# wiz16b8m4ct3_0_WIZ16B8M4CT3 register map
Vendor: Texas Instruments
Registers are 32-bit, read-write, reset 0x0 unless marked. A register's access mark holds for its fields unless they carry their own. Offsets are as the file gives them; [hi:lo] are bit positions.

## wiz16b8m4ct3_0_WIZ16B8M4CT3 (part 6 of 12)
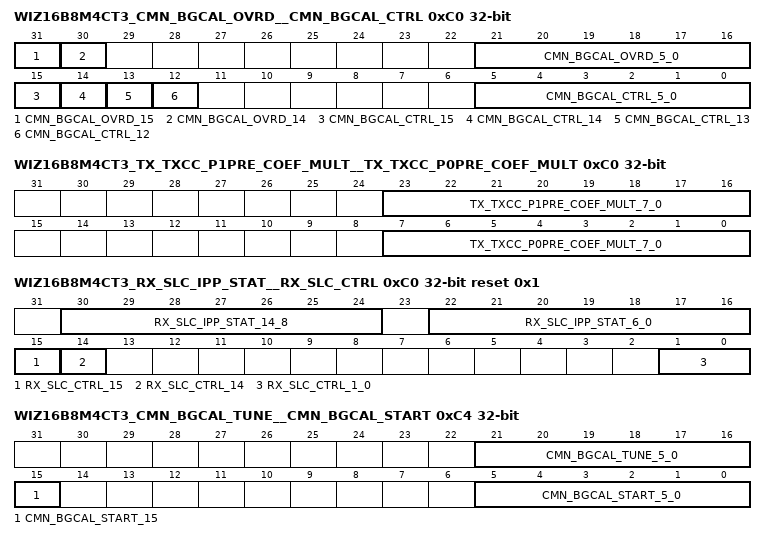
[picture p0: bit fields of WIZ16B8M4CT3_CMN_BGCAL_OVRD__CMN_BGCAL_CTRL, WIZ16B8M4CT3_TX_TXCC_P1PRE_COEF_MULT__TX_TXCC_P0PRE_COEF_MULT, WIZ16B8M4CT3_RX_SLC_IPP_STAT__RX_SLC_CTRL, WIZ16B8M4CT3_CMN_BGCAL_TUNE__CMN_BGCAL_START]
0xC0 WIZ16B8M4CT3_CMN_BGCAL_OVRD__CMN_BGCAL_CTRL access per field
  [31] CMN_BGCAL_OVRD_15 rw — Bandgap code override enable: Activation (1'b1) of this register bit allows the bandgap codes determined during the automatic calibration process to be overridden. The override value is specified using the bandgap code override value field of this register. Note: The value of this field must not be changed while the calibration function is running.
  [30] CMN_BGCAL_OVRD_14 rw — Analog calibration enable override: Activation (1'b1) of this register bit will force the analog calibration circuits to be enabled by activating the cmnda_bias_bgcal_en enable. Note: The value of this field must not be changed while the calibration function is running.
  [21:16] CMN_BGCAL_OVRD_5_0 rw — Bandgap code override value: These bits are used to override the bandgap code determined during the automatic calibration process. The code written to these bits is valid when the bandgap code override enable bit in this register is active. The codes in this field correspond to those described in the bandgap calibration code field in the Bandgap calibration control register on page 106. Note: The value of this field must not be changed while the calibration function is running.
  [15] CMN_BGCAL_CTRL_15 rw — Start bandgap calibration: Activating (1'b1) this bit will start the bandgap calibration process. This signal must remain active until the calibration process is complete. To start another calibration process, this register must first be set inactive (1'b0) until the bandbap calibration process done bit in this register is cleared. Note: This bit is intended to be for diagnostics purposes only. This calibration process is automatically activated internally by the startup state machine. When using this bit, the user must wait until after the internally activated process completes.
  [14] CMN_BGCAL_CTRL_14 ro — Bandgap calibration process done: This bit will be set to 1'b1 when the bandgap calibration process is complete. It will be cleared by cmn_reset_n, or by the deactivation of the start bandgap calibration bit in this register after calibration is complete. Note: This bit is intended to be for diagnostics purposes only. Note: This bit is not likely to be observed as being set after internal automatic calibration is complete, because the internally generated run signal will be driven inactive immediately after the done signal is activated, and therefore the internal done signal will be cleared. Note: Three cmn_ref_clk cycles are required after the start of the calibration process to clear this signal.
  [13] CMN_BGCAL_CTRL_13 ro — No analog calibration response : This signal indicates that the calibration function has gone through the entire calibration process, reached the final calibration value, and the analog has not responded indicating that a valid calibration value has been reached. Note: Due to the nature of the calibration process, it is not possible to determine if the analog responded or not for the lowest code of 5'b10001. The reason for this is, when sequencing to lower codes, the calibration function is looking for the analog response to transition from 1'b1 to 1'b0. If the lowest calibration code is the correct code, the analog will respond with 1'b1, and the algorithm can't sequence to a lower code to look for the transition from 1'b1 to 1'b0. Similarly, if the analog is not responding, it is not possible to sequence to a lower code to detect this. Therefore, even when the calibration function selects this calibration code as valid, this bit will be set.
  [12] CMN_BGCAL_CTRL_12 ro — Current analog comparator response: This is the current state of the analog comparator response signal (cmnda_bias_bgcal_comp). This signal is not synchronized, and is provided for diagnostic purposes only.
  [5:0] CMN_BGCAL_CTRL_5_0 ro — Bandgap calibration code: This is the calibration code that was determined by the bandgap calibration process. The following indicates how this encoding maps to the cmnda_bias_bgcal_up and cmnda_bias_bgcal_azsel signals going to the analog bandgap function. The 6 bit value on the left is the value of this field. The 1 bit value on the right corresponds to the value of cmnda_bias_bgcal_up. The 5 bit field corresponds to the value of cmnda_bias_bgcal_azsel. 6'b011111 : 1'b1, 5'b11111 6'b011110 : 1'b1, 5'b11110 ... 6'b000010 : 1'b1, 5'b00010 6'b000001 : 1'b1, 5'b00001 6'b000000 : 1'b1, 5'b00000 6'b111111 : 1'b0, 5'b00001 6'b111110 : 1'b0, 5'b00010 ... 6'b100010 : 1'b0, 5'b11110 6'b100001 : 1'b0, 5'b11111
0xC0 WIZ16B8M4CT3_TX_TXCC_P1PRE_COEF_MULT__TX_TXCC_P0PRE_COEF_MULT
  [23:16] TX_TXCC_P1PRE_COEF_MULT_7_0 — Preset 1 pre emphasis coefficient multiplier value : The value in this field specifies the multiplier value used to generate the preset 1 pre emphasis coefficient value from the FS value. The following describes the multiplier value each bit in this field corresponds to. Bit 7 : 128/128 = 1.000000 Bit 6 : 64/128 = 0.500000 Bit 5 : 32/128 = 0.250000 Bit 4 : 16/128 = 0.125000 Bit 3 : 8/128 = 0.062500 Bit 2 : 4/128 = 0.031250 Bit 1 : 2/128 = 0.015625 Bit 0 : 1/128 = 0.0078125 Note: The output of the multiplier is 6 bits wide. It is possible to set the multiplier value here to a sufficiently large value to cause the multiplier result to be such that it can't be represented by a 6 bit value. In such a case, the multiplier output will be driven to 6'b111111.
  [7:0] TX_TXCC_P0PRE_COEF_MULT_7_0 — Preset 0 pre emphasis coefficient multiplier value : The value in this field specifies the multiplier value used to generate the preset 0 pre emphasis coefficient value from the FS value. The following describes the multiplier value each bit in this field corresponds to. Bit 7 : 128/128 = 1.000000 Bit 6 : 64/128 = 0.500000 Bit 5 : 32/128 = 0.250000 Bit 4 : 16/128 = 0.125000 Bit 3 : 8/128 = 0.062500 Bit 2 : 4/128 = 0.031250 Bit 1 : 2/128 = 0.015625 Bit 0 : 1/128 = 0.0078125 Note: The output of the multiplier is 6 bits wide. It is possible to set the multiplier value here to a sufficiently large value to cause the multiplier result to be such that it can't be represented by a 6 bit value. In such a case, the multiplier output will be driven to 6'b111111.
0xC0 WIZ16B8M4CT3_RX_SLC_IPP_STAT__RX_SLC_CTRL access per field reset 0x1
  [30:24] RX_SLC_IPP_STAT_14_8 ro — I even latch receiver sampler calibration DAC value: This field contains the current value that the RX sampler latch calibration module has calculated to drive to the DAC that controls the offset for the I even latch in the analog sampler component.
  [22:16] RX_SLC_IPP_STAT_6_0 ro — I odd latch receiver sampler calibration DAC value: This field contains the current value that the RX sampler latch calibration module has calculated to drive to the DAC that controls the offset for the I odd latch in the analog sampler component.
  [15] RX_SLC_CTRL_15 rw — Start RX sampler latch calibration: Activating (1'b1) this bit will start the RX sampler latch calibration process. This bit should remain active until the RX sampler latch calibration process is complete. To start another RX sampler latch calibration process, this bit must first be inactive (1'b0) until the RX sampler latch calibration done bit goes inactive. Note: This bit is intended to be for diagnostics purposes only. This calibration process is automatically activated internally, by the power state machine. When using this bit, the user must wait until after the internally activated process completes.
  [14] RX_SLC_CTRL_14 ro — RX sampler latch calibration process done: This bit will be set to 1'b1 when the RX sampler latch calibration process is complete. It will be cleared by cmn_reset_n, or by clearing the start RX sampler latch process bit. Note: This bit is intended to be for diagnostics purposes only. Note: This bit is not likely to be observed as being set after internal automatic calibration is complete, because the internally generated run signal will be driven inactive immediately after the done signal is activated, and therefore the internal done signal will be cleared.
  [1:0] RX_SLC_CTRL_1_0 rw — RX sampler latch calibration scaler: This field specifies the scaler value used for the input data accumulator. The following is the encoding used for this signal.
0xC4 WIZ16B8M4CT3_CMN_BGCAL_TUNE__CMN_BGCAL_START
  [21:16] CMN_BGCAL_TUNE_5_0 — Bandgap calibration tune value: The value of this field is added to the automatically calibrated code, or the override code if override is enabled. Note: This value is a twos complement value, so the calibrated code can be increased or decreased.
  [15] CMN_BGCAL_START_15 — Bandgap calibration direction: This controls the direction that the automatic calibration process steps the calibration codes in. 1'b0 : From 4'b1001 to 4'b0111. 1'b1 : From 4'b0111 to 4'b0000.
  [5:0] CMN_BGCAL_START_5_0 — Start bandgap calibration code: This is the calibration code that the calibration process starts with when automatic calibration is run. The codes in this field correspond to those described in the bandgap calibration code field in the Bandgap calibration control register on page 106.
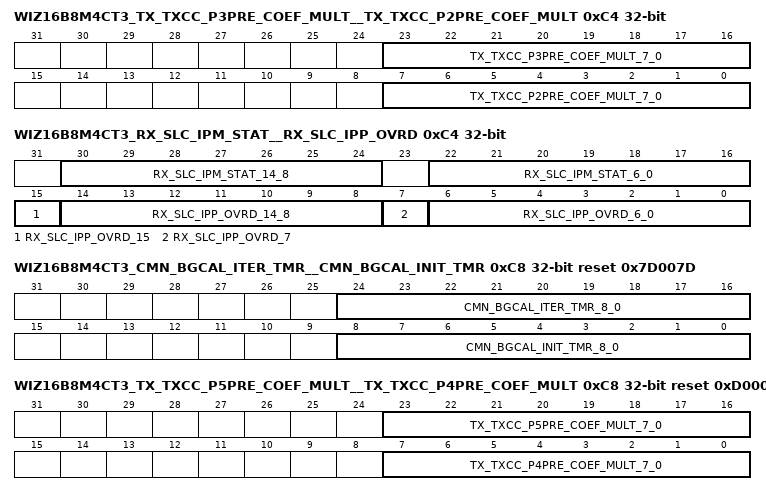
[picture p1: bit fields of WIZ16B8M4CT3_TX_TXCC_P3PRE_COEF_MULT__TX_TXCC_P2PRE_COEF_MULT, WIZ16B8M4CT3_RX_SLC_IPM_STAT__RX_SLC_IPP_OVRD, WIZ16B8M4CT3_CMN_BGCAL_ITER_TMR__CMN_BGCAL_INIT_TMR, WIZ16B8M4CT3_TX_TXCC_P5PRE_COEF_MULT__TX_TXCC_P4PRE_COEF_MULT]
0xC4 WIZ16B8M4CT3_TX_TXCC_P3PRE_COEF_MULT__TX_TXCC_P2PRE_COEF_MULT
  [23:16] TX_TXCC_P3PRE_COEF_MULT_7_0 — Preset 3 pre emphasis coefficient multiplier value : The value in this field specifies the multiplier value used to generate the preset 3 pre emphasis coefficient value from the FS value. The following describes the multiplier value each bit in this field corresponds to. Bit 7 : 128/128 = 1.000000 Bit 6 : 64/128 = 0.500000 Bit 5 : 32/128 = 0.250000 Bit 4 : 16/128 = 0.125000 Bit 3 : 8/128 = 0.062500 Bit 2 : 4/128 = 0.031250 Bit 1 : 2/128 = 0.015625 Bit 0 : 1/128 = 0.0078125 Note: The output of the multiplier is 6 bits wide. It is possible to set the multiplier value here to a sufficiently large value to cause the multiplier result to be such that it can't be represented by a 6 bit value. In such a case, the multiplier output will be driven to 6'b111111.
  [7:0] TX_TXCC_P2PRE_COEF_MULT_7_0 — Preset 2 pre emphasis coefficient multiplier value : The value in this field specifies the multiplier value used to generate the preset 2 pre emphasis coefficient value from the FS value. The following describes the multiplier value each bit in this field corresponds to. Bit 7 : 128/128 = 1.000000 Bit 6 : 64/128 = 0.500000 Bit 5 : 32/128 = 0.250000 Bit 4 : 16/128 = 0.125000 Bit 3 : 8/128 = 0.062500 Bit 2 : 4/128 = 0.031250 Bit 1 : 2/128 = 0.015625 Bit 0 : 1/128 = 0.0078125 Note: The output of the multiplier is 6 bits wide. It is possible to set the multiplier value here to a sufficiently large value to cause the multiplier result to be such that it can't be represented by a 6 bit value. In such a case, the multiplier output will be driven to 6'b111111.
0xC4 WIZ16B8M4CT3_RX_SLC_IPM_STAT__RX_SLC_IPP_OVRD access per field
  [30:24] RX_SLC_IPM_STAT_14_8 ro — I even latch receiver sampler calibration DAC value: This field contains the current value that the RX sampler latch calibration module has calculated to drive to the DAC that controls the offset for the I even latch in the analog sampler component.
  [22:16] RX_SLC_IPM_STAT_6_0 ro — I odd latch receiver sampler calibration DAC value: This field contains the current value that the RX sampler latch calibration module has calculated to drive to the DAC that controls the offset for the I odd latch in the analog sampler component.
  [15] RX_SLC_IPP_OVRD_15 rw — I even latch receiver sampler calibration DAC override enable: When this bit is active (1'b1), the value in the I even latch receiver sampler calibration DAC override value field of this register will override the calibrated value for the I even sampler latch.
  [14:8] RX_SLC_IPP_OVRD_14_8 rw — I even latch receiver sampler calibration DAC override value: This field contains the value that can be used to override the calibrated value for the I even sampler latch. Note: The value of this field is a signed magnitude number with a range of 5'b11111 (min) to 5'b01111 (max). A value of 5'b10000 (-0) is not valid.
  [7] RX_SLC_IPP_OVRD_7 rw — I odd latch receiver sampler calibration DAC override enable: When this bit is active (1'b1), the value in the I odd latch receiver sampler calibration DAC override value field of this register will override the calibrated value for the I odd sampler latch.
  [6:0] RX_SLC_IPP_OVRD_6_0 rw — I odd latch receiver sampler calibration DAC override value: This field contains the value that can be used to override the calibrated value for the I odd sampler latch. Note: The value of this field is a signed magnitude number with a range of 5'b11111 (min) to 5'b01111 (max). A value of 5'b10000 (-0) is not valid.
0xC8 WIZ16B8M4CT3_CMN_BGCAL_ITER_TMR__CMN_BGCAL_INIT_TMR reset 0x7D007D
  [24:16] CMN_BGCAL_ITER_TMR_8_0 — Iteration wait timer value: This is the number of cmn_ref_clk clocks to wait between when a value is placed on the bandgap calibration signals going to the analog, and when the comparator value coming from the analog circuits can be checked. Note: This results in the minimum number of cmn_ref_clk clocks required to wait 5 uSec. Note: This should never be set to a value of less than 3.
  [8:0] CMN_BGCAL_INIT_TMR_8_0 — Initialization wait timer value: This is the number of cmn_ref_clk clocks to wait between when the analog bandgap calibration circuits are enabled, and when the first values are placed on the bandgap calibration signals going to the analog. Note: This results in the minimum number of cmn_ref_clk clocks required to wait 5 uSec. Note: This should never be set to a value of less than 1.
0xC8 WIZ16B8M4CT3_TX_TXCC_P5PRE_COEF_MULT__TX_TXCC_P4PRE_COEF_MULT reset 0xD0000
  [23:16] TX_TXCC_P5PRE_COEF_MULT_7_0 — Preset 5 pre emphasis coefficient multiplier value : The value in this field specifies the multiplier value used to generate the preset 5 pre emphasis coefficient value from the FS value. The following describes the multiplier value each bit in this field corresponds to. Bit 7 : 128/128 = 1.000000 Bit 6 : 64/128 = 0.500000 Bit 5 : 32/128 = 0.250000 Bit 4 : 16/128 = 0.125000 Bit 3 : 8/128 = 0.062500 Bit 2 : 4/128 = 0.031250 Bit 1 : 2/128 = 0.015625 Bit 0 : 1/128 = 0.0078125 Note: The output of the multiplier is 6 bits wide. It is possible to set the multiplier value here to a sufficiently large value to cause the multiplier result to be such that it can't be represented by a 6 bit value. In such a case, the multiplier output will be driven to 6'b111111.
  [7:0] TX_TXCC_P4PRE_COEF_MULT_7_0 — Preset 4 pre emphasis coefficient multiplier value : The value in this field specifies the multiplier value used to generate the preset 4 pre emphasis coefficient value from the FS value. The following describes the multiplier value each bit in this field corresponds to. Bit 7 : 128/128 = 1.000000 Bit 6 : 64/128 = 0.500000 Bit 5 : 32/128 = 0.250000 Bit 4 : 16/128 = 0.125000 Bit 3 : 8/128 = 0.062500 Bit 2 : 4/128 = 0.031250 Bit 1 : 2/128 = 0.015625 Bit 0 : 1/128 = 0.0078125 Note: The output of the multiplier is 6 bits wide. It is possible to set the multiplier value here to a sufficiently large value to cause the multiplier result to be such that it can't be represented by a 6 bit value. In such a case, the multiplier output will be driven to 6'b111111.
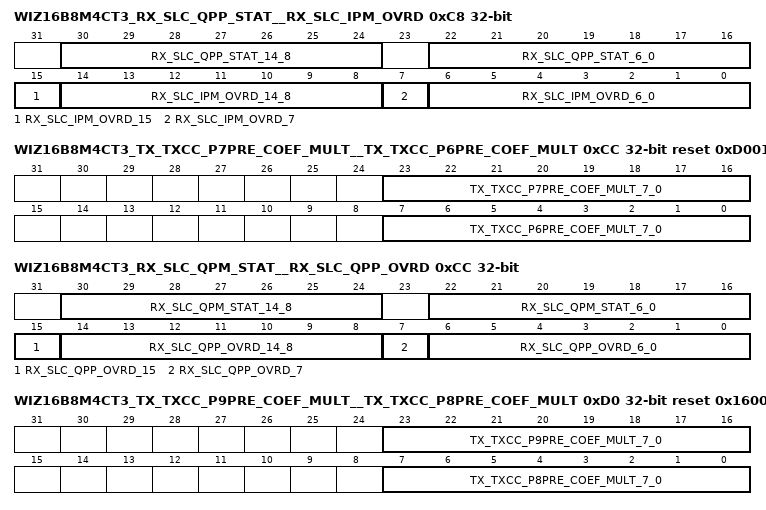
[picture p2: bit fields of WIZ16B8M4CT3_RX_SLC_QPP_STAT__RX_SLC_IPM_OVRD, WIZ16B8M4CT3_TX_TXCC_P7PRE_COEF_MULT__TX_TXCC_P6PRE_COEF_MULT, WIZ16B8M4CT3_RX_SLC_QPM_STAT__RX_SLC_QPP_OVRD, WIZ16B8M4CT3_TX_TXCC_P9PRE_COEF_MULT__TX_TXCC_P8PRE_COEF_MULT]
0xC8 WIZ16B8M4CT3_RX_SLC_QPP_STAT__RX_SLC_IPM_OVRD access per field
  [30:24] RX_SLC_QPP_STAT_14_8 ro — Q even latch receiver sampler calibration DAC value: This field contains the current value that the RX sampler latch calibration module has calculated to drive to the DAC that controls the offset for the Q even latch in the analog sampler component.
  [22:16] RX_SLC_QPP_STAT_6_0 ro — Q odd latch receiver sampler calibration DAC value: This field contains the current value that the RX sampler latch calibration module has calculated to drive to the DAC that controls the offset for the Q odd latch in the analog sampler component.
  [15] RX_SLC_IPM_OVRD_15 rw — I eve latch receiver sampler calibration DAC override enable: When this bit is active (1'b1), the value in the I even latch receiver sampler calibration DAC override value field of this register will override the calibrated value for the I even sampler latch.
  [14:8] RX_SLC_IPM_OVRD_14_8 rw — I even latch receiver sampler calibration DAC override value: This field contains the value that can be used to override the calibrated value for the I even sampler latch. Note: The value of this field is a signed magnitude number with a range of 5'b11111 (min) to 5'b01111 (max). A value of 5'b10000 (-0) is not valid.
  [7] RX_SLC_IPM_OVRD_7 rw — I odd latch receiver sampler calibration DAC override enable: When this bit is active (1'b1), the value in the I odd latch receiver sampler calibration DAC override value field of this register will override the calibrated value for the I odd sampler latch.
  [6:0] RX_SLC_IPM_OVRD_6_0 rw — I odd latch receiver sampler calibration DAC override value: This field contains the value that can be used to override the calibrated value for the I odd sampler latch. Note: The value of this field is a signed magnitude number with a range of 5'b11111 (min) to 5'b01111 (max). A value of 5'b10000 (-0) is not valid.
0xCC WIZ16B8M4CT3_TX_TXCC_P7PRE_COEF_MULT__TX_TXCC_P6PRE_COEF_MULT reset 0xD0010
  [23:16] TX_TXCC_P7PRE_COEF_MULT_7_0 — Preset 7 pre emphasis coefficient multiplier value : The value in this field specifies the multiplier value used to generate the preset 7 pre emphasis coefficient value from the FS value. The following describes the multiplier value each bit in this field corresponds to. Bit 7 : 128/128 = 1.000000 Bit 6 : 64/128 = 0.500000 Bit 5 : 32/128 = 0.250000 Bit 4 : 16/128 = 0.125000 Bit 3 : 8/128 = 0.062500 Bit 2 : 4/128 = 0.031250 Bit 1 : 2/128 = 0.015625 Bit 0 : 1/128 = 0.0078125 Note: The output of the multiplier is 6 bits wide. It is possible to set the multiplier value here to a sufficiently large value to cause the multiplier result to be such that it can't be represented by a 6 bit value. In such a case, the multiplier output will be driven to 6'b111111.
  [7:0] TX_TXCC_P6PRE_COEF_MULT_7_0 — Preset 6 pre emphasis coefficient multiplier value : The value in this field specifies the multiplier value used to generate the preset 6 pre emphasis coefficient value from the FS value. The following describes the multiplier value each bit in this field corresponds to. Bit 7 : 128/128 = 1.000000 Bit 6 : 64/128 = 0.500000 Bit 5 : 32/128 = 0.250000 Bit 4 : 16/128 = 0.125000 Bit 3 : 8/128 = 0.062500 Bit 2 : 4/128 = 0.031250 Bit 1 : 2/128 = 0.015625 Bit 0 : 1/128 = 0.0078125 Note: The output of the multiplier is 6 bits wide. It is possible to set the multiplier value here to a sufficiently large value to cause the multiplier result to be such that it can't be represented by a 6 bit value. In such a case, the multiplier output will be driven to 6'b111111.
0xCC WIZ16B8M4CT3_RX_SLC_QPM_STAT__RX_SLC_QPP_OVRD access per field
  [30:24] RX_SLC_QPM_STAT_14_8 ro — Q even latch receiver sampler calibration DAC value: This field contains the current value that the RX sampler latch calibration module has calculated to drive to the DAC that controls the offset for the Q even latch in the analog sampler component.
  [22:16] RX_SLC_QPM_STAT_6_0 ro — Q odd latch receiver sampler calibration DAC value: This field contains the current value that the RX sampler latch calibration module has calculated to drive to the DAC that controls the offset for the Q odd latch in the analog sampler component.
  [15] RX_SLC_QPP_OVRD_15 rw — Q even latch receiver sampler calibration DAC override enable: When this bit is active (1'b1), the value in the Q even latch receiver sampler calibration DAC override value field of this register will override the calibrated value for the Q even sampler latch.
  [14:8] RX_SLC_QPP_OVRD_14_8 rw — Q even latch receiver sampler calibration DAC override value: This field contains the value that can be used to override the calibrated value for the Q even sampler latch. Note: The value of this field is a signed magnitude number with a range of 5'b11111 (min) to 5'b01111 (max). A value of 5'b10000 (-0) is not valid.
  [7] RX_SLC_QPP_OVRD_7 rw — Q odd latch receiver sampler calibration DAC override enable: When this bit is active (1'b1), the value in the Q odd latch receiver sampler calibration DAC override value field of this register will override the calibrated value for the Q odd sampler latch.
  [6:0] RX_SLC_QPP_OVRD_6_0 rw — Q odd latch receiver sampler calibration DAC override value: This field contains the value that can be used to override the calibrated value for the Q odd sampler latch. Note: The value of this field is a signed magnitude number with a range of 5'b11111 (min) to 5'b01111 (max). A value of 5'b10000 (-0) is not valid.
0xD0 WIZ16B8M4CT3_TX_TXCC_P9PRE_COEF_MULT__TX_TXCC_P8PRE_COEF_MULT reset 0x160010
  [23:16] TX_TXCC_P9PRE_COEF_MULT_7_0 — Preset 9 pre emphasis coefficient multiplier value : The value in this field specifies the multiplier value used to generate the preset 9 pre emphasis coefficient value from the FS value. The following describes the multiplier value each bit in this field corresponds to. Bit 7 : 128/128 = 1.000000 Bit 6 : 64/128 = 0.500000 Bit 5 : 32/128 = 0.250000 Bit 4 : 16/128 = 0.125000 Bit 3 : 8/128 = 0.062500 Bit 2 : 4/128 = 0.031250 Bit 1 : 2/128 = 0.015625 Bit 0 : 1/128 = 0.0078125 Note: The output of the multiplier is 6 bits wide. It is possible to set the multiplier value here to a sufficiently large value to cause the multiplier result to be such that it can't be represented by a 6 bit value. In such a case, the multiplier output will be driven to 6'b111111.
  [7:0] TX_TXCC_P8PRE_COEF_MULT_7_0 — Preset 8 pre emphasis coefficient multiplier value : The value in this field specifies the multiplier value used to generate the preset 8 pre emphasis coefficient value from the FS value. The following describes the multiplier value each bit in this field corresponds to. Bit 7 : 128/128 = 1.000000 Bit 6 : 64/128 = 0.500000 Bit 5 : 32/128 = 0.250000 Bit 4 : 16/128 = 0.125000 Bit 3 : 8/128 = 0.062500 Bit 2 : 4/128 = 0.031250 Bit 1 : 2/128 = 0.015625 Bit 0 : 1/128 = 0.0078125 Note: The output of the multiplier is 6 bits wide. It is possible to set the multiplier value here to a sufficiently large value to cause the multiplier result to be such that it can't be represented by a 6 bit value. In such a case, the multiplier output will be driven to 6'b111111.
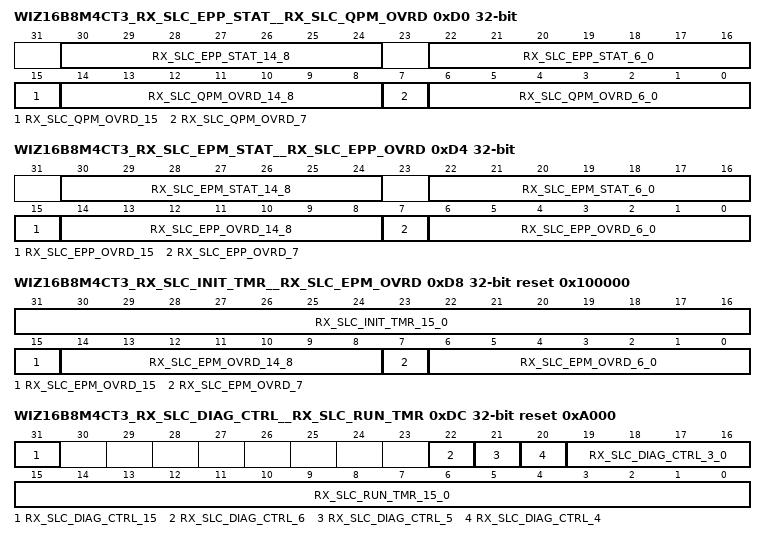
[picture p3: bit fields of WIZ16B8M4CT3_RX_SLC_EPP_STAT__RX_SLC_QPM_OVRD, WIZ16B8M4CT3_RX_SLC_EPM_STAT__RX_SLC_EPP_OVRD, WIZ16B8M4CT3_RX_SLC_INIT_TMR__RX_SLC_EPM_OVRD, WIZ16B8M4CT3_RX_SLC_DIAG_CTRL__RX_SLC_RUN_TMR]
0xD0 WIZ16B8M4CT3_RX_SLC_EPP_STAT__RX_SLC_QPM_OVRD access per field
  [30:24] RX_SLC_EPP_STAT_14_8 ro — e even latch receiver sampler calibration DAC value: This field contains the current value that the RX sampler latch calibration module has calculated to drive to the DAC that controls the offset for the e even latch in the analog sampler component.
  [22:16] RX_SLC_EPP_STAT_6_0 ro — e odd latch receiver sampler calibration DAC value: This field contains the current value that the RX sampler latch calibration module has calculated to drive to the DAC that controls the offset for the e odd latch in the analog sampler component.
  [15] RX_SLC_QPM_OVRD_15 rw — Q even latch receiver sampler calibration DAC override enable: When this bit is active (1'b1), the value in the Q even latch receiver sampler calibration DAC override value field of this register will override the calibrated value for the Q even sampler latch.
  [14:8] RX_SLC_QPM_OVRD_14_8 rw — Q even latch receiver sampler calibration DAC override value: This field contains the value that can be used to override the calibrated value for the Q even sampler latch. Note: The value of this field is a signed magnitude number with a range of 5'b11111 (min) to 5'b01111 (max). A value of 5'b10000 (-0) is not valid.
  [7] RX_SLC_QPM_OVRD_7 rw — Q odd latch receiver sampler calibration DAC override enable: When this bit is active (1'b1), the value in the Q odd latch receiver sampler calibration DAC override value field of this register will override the calibrated value for the Q odd sampler latch.
  [6:0] RX_SLC_QPM_OVRD_6_0 rw — Q odd latch receiver sampler calibration DAC override value: This field contains the value that can be used to override the calibrated value for the Q odd sampler latch. Note: The value of this field is a signed magnitude number with a range of 5'b11111 (min) to 5'b01111 (max). A value of 5'b10000 (-0) is not valid.
0xD4 WIZ16B8M4CT3_RX_SLC_EPM_STAT__RX_SLC_EPP_OVRD access per field
  [30:24] RX_SLC_EPM_STAT_14_8 ro — e even latch receiver sampler calibration DAC value: This field contains the current value that the RX sampler latch calibration module has calculated to drive to the DAC that controls the offset for the e even latch in the analog sampler component.
  [22:16] RX_SLC_EPM_STAT_6_0 ro — e odd latch receiver sampler calibration DAC value: This field contains the current value that the RX sampler latch calibration module has calculated to drive to the DAC that controls the offset for the e odd latch in the analog sampler component.
  [15] RX_SLC_EPP_OVRD_15 rw — e even latch receiver sampler calibration DAC override enable: When this bit is active (1'b1), the value in the e even latch receiver sampler calibration DAC override value field of this register will override the calibrated value for the e even sampler latch.
  [14:8] RX_SLC_EPP_OVRD_14_8 rw — e even latch receiver sampler calibration DAC override value: This field contains the value that can be used to override the calibrated value for the e even sampler latch. Note: The value of this field is a signed magnitude number with a range of 5'b11111 (min) to 5'b01111 (max). A value of 5'b10000 (-0) is not valid.
  [7] RX_SLC_EPP_OVRD_7 rw — e odd latch receiver sampler calibration DAC override enable: When this bit is active (1'b1), the value in the e odd latch receiver sampler calibration DAC override value field of this register will override the calibrated value for the e odd sampler latch.
  [6:0] RX_SLC_EPP_OVRD_6_0 rw — e odd latch receiver sampler calibration DAC override value: This field contains the value that can be used to override the calibrated value for the e odd sampler latch. Note: The value of this field is a signed magnitude number with a range of 5'b11111 (min) to 5'b01111 (max). A value of 5'b10000 (-0) is not valid.
0xD8 WIZ16B8M4CT3_RX_SLC_INIT_TMR__RX_SLC_EPM_OVRD reset 0x100000
  [31:16] RX_SLC_INIT_TMR_15_0 — RX sampler latch calibration initialization timer value : This is the value that will be used for the RX sampler latch calibration initialization timer, which controls the time the rxda_sampler_latch_cal_en is held active prior to the individual calibration processes being kicked off. Note: This register should not be set to 16'h0000.
  [15] RX_SLC_EPM_OVRD_15 — e even latch receiver sampler calibration DAC override enable: When this bit is active (1'b1), the value in the e even latch receiver sampler calibration DAC override value field of this register will override the calibrated value for the e even sampler latch.
  [14:8] RX_SLC_EPM_OVRD_14_8 — e even latch receiver sampler calibration DAC override value: This field contains the value that can be used to override the calibrated value for the e even sampler latch. Note: The value of this field is a signed magnitude number with a range of 5'b11111 (min) to 5'b01111 (max). A value of 5'b10000 (-0) is not valid.
  [7] RX_SLC_EPM_OVRD_7 — e odd latch receiver sampler calibration DAC override enable: When this bit is active (1'b1), the value in the e odd latch receiver sampler calibration DAC override value field of this register will override the calibrated value for the e odd sampler latch.
  [6:0] RX_SLC_EPM_OVRD_6_0 — e odd latch receiver sampler calibration DAC override value: This field contains the value that can be used to override the calibrated value for the e odd sampler latch. Note: The value of this field is a signed magnitude number with a range of 5'b11111 (min) to 5'b01111 (max). A value of 5'b10000 (-0) is not valid.
0xDC WIZ16B8M4CT3_RX_SLC_DIAG_CTRL__RX_SLC_RUN_TMR reset 0xA000
  [31] RX_SLC_DIAG_CTRL_15 — Diagnostic control enable : This bit enables the selected RX sampler latch calibration data sub module for diagnostic purposes. Note: The diagnostic control override select field must be set to select the desired RX sampler latch calibration data sub module when this bit is set. This bit MUST also be cleared before changing the value of the diagnostic control override select field. Note: When these diagnostic features are used, the user must disable the respective automatic calibration functions in the RX sampler latch calibration disable register (!) on page 247. Due to the way this is implemented, if a given i sampler latch calibration function is being controlled by the diagnostic features here, all of the i sampler calibration functions must be disabled in the RX sampler latch calibration disable register (!) on page 247. The same is required for both the e and q sampler latch calibration functions.
  [22] RX_SLC_DIAG_CTRL_6 — Voter override neg : When enabled using the voter override enable bit in this register, writing a 1'b1 in this register bit will force the voter in the selected RX sampler latch calibration data sub module to activate the voter neg signal for a single clock cycle. Note : This bit must be cleared after each time it is enabled, in order to perform follow on voter override functions with this bit. Note : It is not valid to activate both the voter override neg and voter override pos at the same time.
  [21] RX_SLC_DIAG_CTRL_5 — Voter override pos : When enabled using the voter override enable bit in this register, writing a 1'b1 in this register bit will force the voter in the selected RX sampler latch calibration data sub module to activate the voter pos signal for a single clock cycle. Note : This bit must be cleared after each time it is enabled, in order to perform follow on voter override functions with this bit. Note : It is not valid to activate both the voter override neg and voter override pos at the same time.
  [20] RX_SLC_DIAG_CTRL_4 — Voter override enable : Setting this bit to a 1'b1 will enable the voter override function in the selected RX sampler latch calibration data sub module. Note : This function is intended to be for diagnostic and verification purposes only. Note : Both the voter override neg and voter override pos bits in this register must be set to 1'b0 when this bit is initially set to 1'b1 when enabling this function.
  [19:16] RX_SLC_DIAG_CTRL_3_0 — Diagnostic control override select : Selects the RX sampler latch calibration data sub module to enable for diagnostic and verification purposes. This field also selects which sub module's rx_sampler_latch_cal_diag output port will be routed to the top level rx_sampler_latch_cal_diag output port. The following are the values used to select the required RX sampler latch calibration data sub module. 4'b0000 : i odd positive coefficient. 4'b0001 : q odd positive coefficient. 4'b0010 : e odd positive coefficient. 4'b0011 : Reserved. 4'b0100 : i odd negative coefficient. 4'b0101 : q odd negative coefficient. 4'b0110 : e odd negative coefficient. 4'b0111 : Reserved. 4'b1000 : i even positive coefficient. 4'b1001 : q even positive coefficient. 4'b1010 : e even positive coefficient. 4'b1011 : Reserved. 4'b1100 : i even negative coefficient. 4'b1101 : q even negative coefficient. 4'b1110 : e even negative coefficient. 4'b1111 : Reserved.
  [15:0] RX_SLC_RUN_TMR_15_0 — RX sampler latch calibration run timer value : This is the value that will be used for the RX sampler latch calibration run timer, which controls the run time for each calibration process. Note: This register should not be set to 16'h0000.
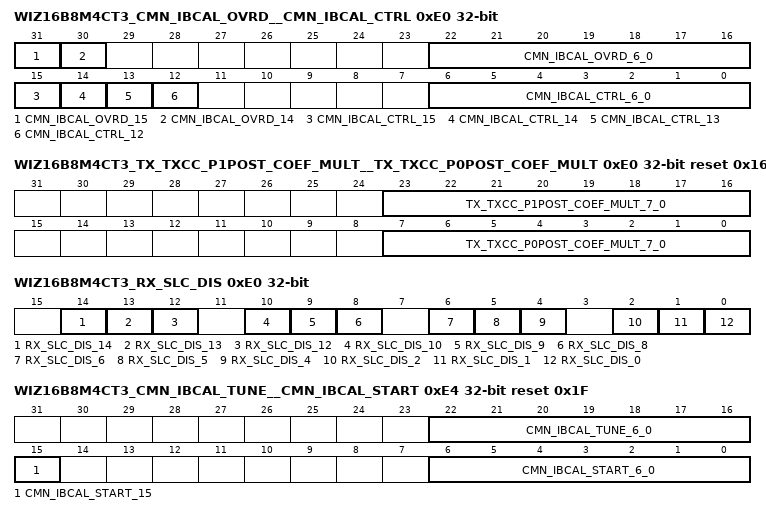
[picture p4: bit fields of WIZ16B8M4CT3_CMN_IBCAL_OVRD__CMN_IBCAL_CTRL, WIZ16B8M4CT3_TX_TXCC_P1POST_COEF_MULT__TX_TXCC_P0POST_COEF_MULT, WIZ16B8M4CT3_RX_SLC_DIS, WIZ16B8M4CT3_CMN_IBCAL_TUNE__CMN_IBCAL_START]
0xE0 WIZ16B8M4CT3_CMN_IBCAL_OVRD__CMN_IBCAL_CTRL access per field
  [31] CMN_IBCAL_OVRD_15 rw — Calibration code override enable: Activation (1'b1) of this register bit allows the calibration code determined during the automatic resistor calibration process to be overridden. The override value is specified using the calibration code override value field of this register.
  [30] CMN_IBCAL_OVRD_14 rw — Analog calibration enable override: Activation (1'b1) of this register bit will force the analog calibration circuits to be enabled by activating the cmnda_ibiascal_en enable and the cmnda_ibiascal_clk clock.
  [22:16] CMN_IBCAL_OVRD_6_0 rw — Calibration code override value: These bits are used to override the calibration code determined during the automatic resistor calibration process. The code written to these bits is valid when the calibration code override enable bit in this register is active. The following are the values for the code: 7'b0000000: Minimum value. 7'b0000001 7'b0000010 7'b0000011 ... 7'b0111110 7'b0111111: Maximum value. Note: The most significant bit is the calibration code sign bit, and is always 1'b0 in this application.
  [15] CMN_IBCAL_CTRL_15 rw — Start calibration: Activating (1'b1) this bit will start the calibration process. This signal must remain active until the calibration process is complete. To start another calibration process, this register must first be set inactive (1'b0) until the calibration process done bit in this register is cleared. Note: This signal is intended to be for diagnostics purposes only. This calibration process is automatically activated internally by the startup state machine. When using this bit, the user must wait until after the internally activated process completes.
  [14] CMN_IBCAL_CTRL_14 ro — Calibration process done: This bit will be set to 1'b1 when the calibration process is complete. It will be cleared by cmn_reset_n, or by the deactivation of the start calibration bit in this register after calibration is complete. Note: This bit is intended to be for diagnostics purposes only. Note: This bit is not likely to be observed as being set after internal automatic calibration is complete, because the internally generated run signal will be driven inactive immediately after the done signal is activated, and therefore the internal done signal will be cleared. Note: Three cmn_ref_clk cycles are required after the start of the resistor calibration process to clear this signal.
  [13] CMN_IBCAL_CTRL_13 ro — No analog calibration response : This signal indicates that the calibration function has gone through the entire calibration process, reached the final calibration value, and the analog has not responded indicating that a valid calibration value has been reached. Note: Due to the nature of the calibration process, it is not possible to determine if the analog responded or not for the lowest code of 7'b00000. The reason for this is, when sequencing to lower codes, the calibration function is looking for the analog response to transition from 1'b1 to 1'b0. If the lowest calibration code is the correct code, the analog will respond with 1'b1, and the algorithm can't sequence to a lower code to look for the transition from 1'b1 to 1'b0. Similarly, if the analog is not responding, it is not possible to sequence to a lower code to detect this. Therefore, even when the calibration function selects this calibration code as valid, this bit will be set.
  [12] CMN_IBCAL_CTRL_12 ro — Current analog comparator response: This is the current state of the analog comparator response signal (cmnda_ibiascal_comp). This signal is not synchronized, and is provided for diagnostic purposes only.
  [6:0] CMN_IBCAL_CTRL_6_0 ro — Calibration code: This is the calibration code that was determined by the calibration process. The following are the values for the code: 7'b0000000: Minimum value. 7'b0000001 7'b0000010 7'b0000011 ... 7'b0111110 7'b0111111: Maximum value. Note: The most significant bit is the calibration code sign bit, and is always 1'b0 in this application. Note: The reset value for this field is with the common calibration power island switched off. In cases where this power island is switched on, the reset value be 7'b0011111.
0xE0 WIZ16B8M4CT3_TX_TXCC_P1POST_COEF_MULT__TX_TXCC_P0POST_COEF_MULT reset 0x160022
  [23:16] TX_TXCC_P1POST_COEF_MULT_7_0 — Preset 1 post emphasis coefficient multiplier value : The value in this field specifies the multiplier value used to generate the preset 1 post emphasis coefficient value from the FS value. The following describes the multiplier value each bit in this field corresponds to. Bit 7 : 128/128 = 1.000000 Bit 6 : 64/128 = 0.500000 Bit 5 : 32/128 = 0.250000 Bit 4 : 16/128 = 0.125000 Bit 3 : 8/128 = 0.062500 Bit 2 : 4/128 = 0.031250 Bit 1 : 2/128 = 0.015625 Bit 0 : 1/128 = 0.0078125 Note: The output of the multiplier is 6 bits wide. It is possible to set the multiplier value here to a sufficiently large value to cause the multiplier result to be such that it can't be represented by a 6 bit value. In such a case, the multiplier output will be driven to 6'b111111.
  [7:0] TX_TXCC_P0POST_COEF_MULT_7_0 — Preset 0 post emphasis coefficient multiplier value : The value in this field specifies the multiplier value used to generate the preset 0 post emphasis coefficient value from the FS value. The following describes the multiplier value each bit in this field corresponds to. Bit 7 : 128/128 = 1.000000 Bit 6 : 64/128 = 0.500000 Bit 5 : 32/128 = 0.250000 Bit 4 : 16/128 = 0.125000 Bit 3 : 8/128 = 0.062500 Bit 2 : 4/128 = 0.031250 Bit 1 : 2/128 = 0.015625 Bit 0 : 1/128 = 0.0078125 Note: The output of the multiplier is 6 bits wide. It is possible to set the multiplier value here to a sufficiently large value to cause the multiplier result to be such that it can't be represented by a 6 bit value. In such a case, the multiplier output will be driven to 6'b111111.
0xE0 WIZ16B8M4CT3_RX_SLC_DIS
  [14] RX_SLC_DIS_14 — e even negative coefficient disable : Writing a 1'b1 to this bit will disable auto calibration for the e even negative coefficient RX sampler latch calibration data sub module.
  [13] RX_SLC_DIS_13 — q even negative coefficient disable : Writing a 1'b1 to this bit will disable auto calibration for the q even negative coefficient RX sampler latch calibration data sub module.
  [12] RX_SLC_DIS_12 — i even negative coefficient disable : Writing a 1'b1 to this bit will disable auto calibration for the i even negative coefficient RX sampler latch calibration data sub module.
  [10] RX_SLC_DIS_10 — e even positive coefficient disable : Writing a 1'b1 to this bit will disable auto calibration for the e even positive coefficient RX sampler latch calibration data sub module.
  [9] RX_SLC_DIS_9 — q even positive coefficient disable : Writing a 1'b1 to this bit will disable auto calibration for the q even positive coefficient RX sampler latch calibration data sub module.
  [8] RX_SLC_DIS_8 — i even positive coefficient disable : Writing a 1'b1 to this bit will disable auto calibration for the i even positive coefficient RX sampler latch calibration data sub module.
  [6] RX_SLC_DIS_6 — e odd negative coefficient disable : Writing a 1'b1 to this bit will disable auto calibration for the e odd negative coefficient RX sampler latch calibration data sub module.
  [5] RX_SLC_DIS_5 — q odd negative coefficient disable : Writing a 1'b1 to this bit will disable auto calibration for the q odd negative coefficient RX sampler latch calibration data sub module.
  [4] RX_SLC_DIS_4 — i odd negative coefficient disable : Writing a 1'b1 to this bit will disable auto calibration for the i odd negative coefficient RX sampler latch calibration data sub module.
  [2] RX_SLC_DIS_2 — e odd positive coefficient disable : Writing a 1'b1 to this bit will disable auto calibration for the e odd positive coefficient RX sampler latch calibration data sub module.
  [1] RX_SLC_DIS_1 — q odd positive coefficient disable : Writing a 1'b1 to this bit will disable auto calibration for the q odd positive coefficient RX sampler latch calibration data sub module.
  [0] RX_SLC_DIS_0 — i odd positive coefficient disable : Writing a 1'b1 to this bit will disable auto calibration for the i odd positive coefficient RX sampler latch calibration data sub module.
0xE4 WIZ16B8M4CT3_CMN_IBCAL_TUNE__CMN_IBCAL_START reset 0x1F
  [22:16] CMN_IBCAL_TUNE_6_0 — Calibration tune value: The value of this field is added to the automatically calibrated code, or the override code if override is enabled. Note: This value is a twos complement value, so the calibrated code can be increased or decreased.
  [15] CMN_IBCAL_START_15 — Calibration direction: This controls the direction that the automatic calibration process steps the calibration codes in. 1'b0 : From 7'b0000000 to 7'b0111111. 1'b1 : From 7'b0111111 to 7'b0000000.
  [6:0] CMN_IBCAL_START_6_0 — Start resistor calibration code: This is the calibration code that the resistor calibration process starts with when automatic calibration is run. The following are the values for the code. 7'b0000000: Minimum value. 7'b0000001 7'b0000010 7'b0000011 ... 7'b0111110 7'b0111111: Maximum value. Note: The most significant bit is the calibration code sign bit, and is always 1'b0 in this application.
